# RTS5918 register map
Vendor: Realtek Semiconductor Corp.; Series: RTS5918 Series; File version: 1.00
CPU: ARMV8MML r0p0, little endian, MPU, FPU, VTOR, 3 interrupt priority bits, 8 SAU regions
Registers are 32-bit, read-write, reset 0x0 unless marked. A register's access mark holds for its fields unless they carry their own. Offsets are from the block's base; [hi:lo] are bit positions; {n}, {i} and the like mark numbered series; 'fields as' and 'values as' point back to an identical list.

## SYSTEM — System Controller
Base 0x40100000
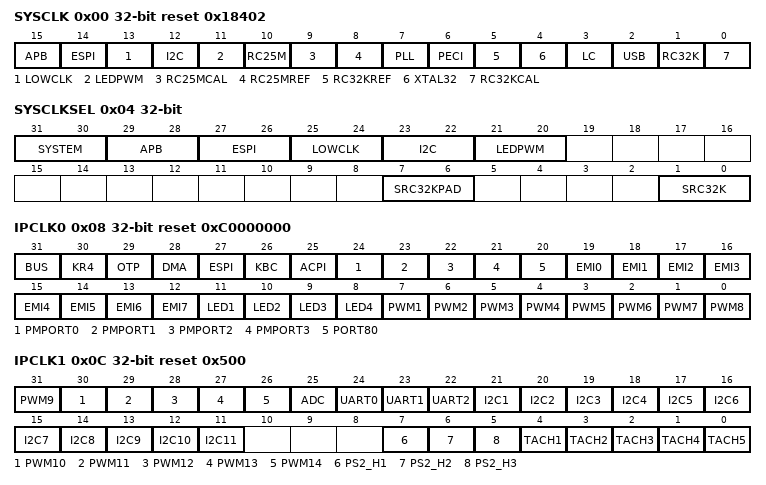
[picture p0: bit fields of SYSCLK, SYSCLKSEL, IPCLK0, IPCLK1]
0x00 SYSCLK reset 0x18402 — SYSCLK POWER ENABLE REGISTER
  [all] fields
    0=DISABLE (CLK_POW disable); 1=ENABLE (CLK_POW enable)
  [15] APB — APB Power
  [14] ESPI — ESPI Power
  [13] LOWCLK — LOWCLK Power
  [12] I2C — I2C Power
  [11] LEDPWM — LEDPWM Power
  [10] RC25M — RC25M Power
  [9] RC25MCAL — RC25M Calibration Power
  [8] RC25MREF — RC25MREF Power
  [7] PLL — PLL Power
  [6] PECI — PECI Power
  [5] RC32KREF — RC32KREF Power
  [4] XTAL32 — XTAL32 Power
  [3] LC — LC Power
  [2] USB — USB Power
  [1] RC32K — RC32K Power
  [0] RC32KCAL — RC32K Calibration Power
0x04 SYSCLKSEL — SYSTEM CLK SELECT REGISTER
  [31:30] SYSTEM — SYSTEM Clock Select
    0=RC25M (select RC25M); 1=PLL (select PLL)
  [29:28] APB — APB Clock Select
    0=RC25M (select RC25M); 1=PLL (select PLL)
  [27:26] ESPI — ESPI Clock Select
    0=RC25M (select RC25M); 1=PLL (select PLL)
  [25:24] LOWCLK — LOW Clock Select
    0=RC25M (select RC25M); 1=PLL (select PLL)
  [23:22] I2C — I2C Clock Select
    0=RC25M (select RC25M); 1=PLL (select PLL)
  [21:20] LEDPWM — select LEDPWM clock source
    0=RC25M (select RC25M); 1=PLL (select PLL); 2=RC32K (select RC32K); 3=XTAL (select XTAL)
  [7:6] SRC32KPAD — select 32K clock pad source
    0=RC32KIN (select RC32K in); 1=XTAL (select XTAL)
  [1:0] SRC32K — select 32K clock source
    0=RC32K (select RC32K); 1=RC25M/750 (select RC25M/750); 2=XTAL (select XTAL)
0x08 IPCLK0 reset 0xC0000000 — IP_CLOCK_0 POWER REGISTER
  [all] fields
    0=DISABLE (ip clock disable); 1=ENABLE (ip clock enable)
  [31] BUS — BUS IP Clock Power
  [30] KR4 — KR4 IP Clock Power
  [29] OTP — OTP IP Clock Power
  [28] DMA — DMA IP Clock Power
  [27] ESPI — ESPI IP Clock Power
  [26] KBC — KBC IP Clock Power
  [25] ACPI — ACPI IP Clock Power
  [24-n] PMPORT{n} (n=0..3) — PMPORT{n} IP Clock Power
  [20] PORT80 — PORT80 IP Clock Power
  [19-n] EMI{n} (n=0..7) — EMI{n} IP Clock Power
  [12-n] LED{n} (n=1..4) — LED{n} IP Clock Power
  [8-n] PWM{n} (n=1..7) — PWM{n} IP Clock Power
  [0] PWM8 — PWM8 IP Clock POWER
0x0C IPCLK1 reset 0x500 — IP_CLOCK_1 POWER EREGISTER
  [all] fields
    0=DISABLE (ip clock disable); 1=ENABLE (ip clock enable)
  [40-n] PWM{n} (n=9..14) — PWM{n} IP Clock Power
  [25] ADC — ADC IP Clock Power
  [24] UART0 — UART0 IP Clock Power
  [23] UART1 — UART1 IP Clock Power
  [22] UART2 — UART2 IP Clock Power
  [22-n] I2C{n} (n=1..11) — I2C{n} IP Clock Power
  [7] PS2_H1 — PS2_H1 IP Clock Power
  [6] PS2_H2 — PS2_H2 IP Clock Power
  [5] PS2_H3 — PS2_H3 IP Clock Power
  [5-n] TACH{n} (n=1..5) — TACH{n} IP Clock Power
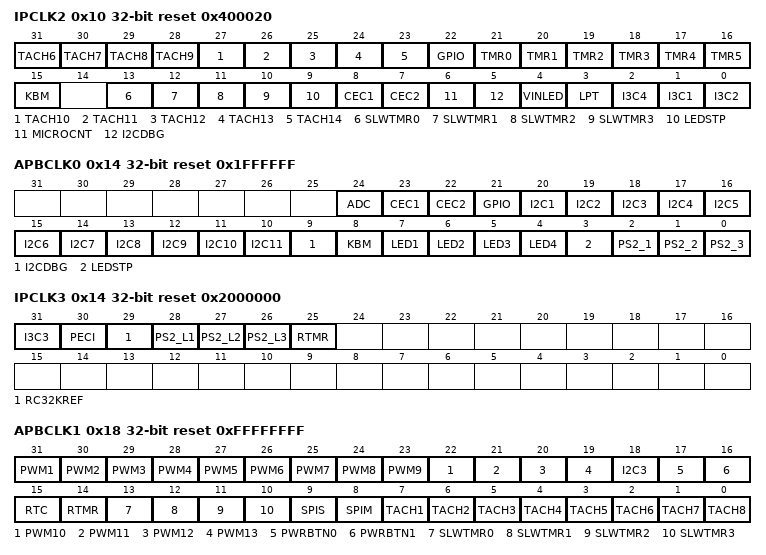
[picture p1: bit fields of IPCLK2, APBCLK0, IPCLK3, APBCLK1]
0x10 IPCLK2 reset 0x400020 — IP_CLOCK_2 POWER EREGISTER
  [all] fields
    0=DISABLE (ip clock disable); 1=ENABLE (ip clock enable)
  [37-n] TACH{n} (n=6..14) — TACH{n} IP Clock Power
  [22] GPIO — GPIO IP Clock Power
  [21-n] TMR{n} (n=0..5) — TMR{n} IP Clock Power
  [15] KBM — KBM IP Clock Power
  [13-n] SLWTMR{n} (n=0..3) — SLWTMR{n} IP Clock Power
  [9] LEDSTP — LEDSTP IP Clock Power
  [8] CEC1 — CEC1 IP Clock Power
  [7] CEC2 — CEC2 IP Clock Power
  [6] MICROCNT — MICROCNT IP Clock Power
  [5] I2CDBG — I2CDBG IP Clock Power
  [4] VINLED — VINLED IP Clock Power
  [3] LPT — LPT IP Clock Power
  [2] I3C4 — I3C4 IP Clock Power
  [1] I3C1 — I3C1 IP Clock Power
  [0] I3C2 — I3C2 IP Clock Power
0x14 APBCLK0 reset 0x1FFFFFF — APB_CLOCK_0 POWER EREGISTER
  [all] fields
    0=DISABLE (apb clock disable); 1=ENABLE (apb clock enable)
  [24] ADC — ADC APB Clock Power
  [23] CEC1 — CEC1 APB Clock Power
  [22] CEC2 — CEC2 APB Clock Power
  [21] GPIO — GPIO APB Clock Power
  [21-n] I2C{n} (n=1..11) — I2C{n} APB Clock Power
  [9] I2CDBG — I2CDBG APB Clock Power
  [8] KBM — KBM APB Clock Power
  [8-n] LED{n} (n=1..4) — LED{n} APB Clock Power
  [3] LEDSTP — LEDSTP APB Clock Power
  [2] PS2_1 — PS2_1 APB Clock Power
  [1] PS2_2 — PS2_2 APB Clock Power
  [0] PS2_3 — PS2_3 APB Clock Power
0x14 IPCLK3 reset 0x2000000 (alternate view of APBCLK0) — IP_CLOCK_3 POWER EREGISTER
  [all] fields
    0=DISABLE (ip clock disable); 1=ENABLE (ip clock enable)
  [31] I3C3 — I3C3 IP Clock Power
  [30] PECI — PECI IP Clock Power
  [29] RC32KREF — RC32KREF IP Clock Power
  [28] PS2_L1 — PS2_L1 Clock Power
  [27] PS2_L2 — PS2_L2 IP Clock Power
  [26] PS2_L3 — PS2_L3 IP Clock Power
  [25] RTMR — RTMR IP Clock Power
0x18 APBCLK1 reset 0xFFFFFFFF — APB_CLOCK_1 POWER EREGISTER
  [all] fields
    0=DISABLE (apb clock disable); 1=ENABLE (apb clock enable)
  [32-n] PWM{n} (n=1..13) — PWM{n} APB Clock Power
  [18] I2C3 — PWM14 APB Clock Power
  [17] PWRBTN0 — PWRBTN0 APB Clock Power
  [16] PWRBTN1 — PWRBTN1 APB Clock Power
  [15] RTC — RTC APB Clock Power
  [14] RTMR — RTMR APB Clock Power
  [13-n] SLWTMR{n} (n=0..3) — SLWTMR{n} APB Clock Power
  [9] SPIS — SPIS APB Clock Power
  [8] SPIM — SPIM APB Clock Power
  [8-n] TACH{n} (n=1..8) — TACH{n} APB Clock Power
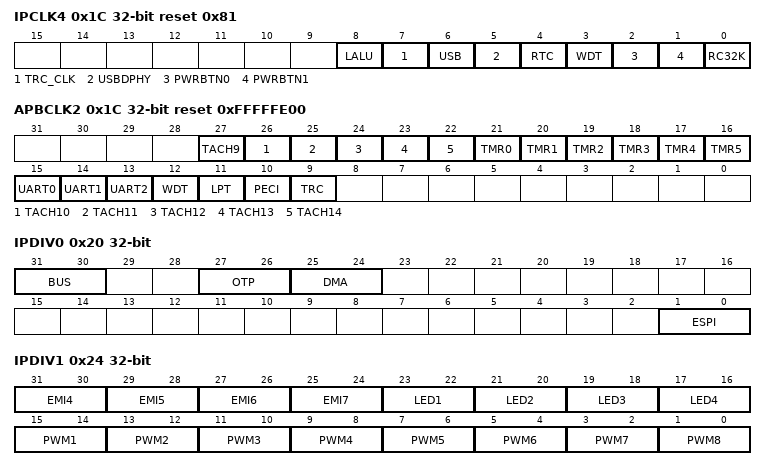
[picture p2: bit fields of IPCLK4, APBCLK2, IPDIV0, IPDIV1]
0x1C IPCLK4 reset 0x81 — IP_CLOCK_4 POWER EREGISTER
  [all] fields
    0=DISABLE (ip clock disable); 1=ENABLE (ip clock enable)
  [8] LALU — LALU IP Clock Power
  [7] TRC_CLK — TRC_CLK IP Clock Power
  [6] USB — USB IP Clock Power
  [5] USBDPHY — USBDPHY IP Clock Power
  [4] RTC — RTC IP Clock Power
  [3] WDT — WDT Clock Power
  [2] PWRBTN0 — PWRBTN0 IP Clock Power
  [1] PWRBTN1 — PWRBTN1 IP Clock Power
  [0] RC32K — RC32K IP Clock Power
0x1C APBCLK2 reset 0xFFFFFE00 (alternate view of IPCLK4) — APB_CLOCK_2 POWER EREGISTER
  [all] fields
    0=DISABLE (apb clock disable); 1=ENABLE (apb clock enable)
  [36-n] TACH{n} (n=9..14) — TACH{n} APB Clock Power
  [21-n] TMR{n} (n=0..5) — TMR{n} APB Clock Power
  [15] UART0 — UART0 APB Clock Power
  [14] UART1 — UART1 APB Clock Power
  [13] UART2 — UART2 APB Clock Power
  [12] WDT — WDT APB Clock Power
  [11] LPT — LPT APB Clock Power
  [10] PECI — PECI APB Clock Power
  [9] TRC — TRC APB Clock Power
0x20 IPDIV0 — IP_CLOCK_DIVIDER_0 REGISTER
  [all] fields
    0=DIV1 (ip clock divide 1); 1=DIV2 (ip clock divide 2); 2=DIV4 (ip clock divide 4); 3=DIV8 (ip clock divide 8)
  [31:30] BUS — BUS IP Clock Divider
  [27:26] OTP — OTP IP Clock Divider
  [25:24] DMA — DMA IP Clock Divider
  [1:0] ESPI — ESPI IP Clock Divider
0x24 IPDIV1 — IP_CLOCK_DIVIDER_1 REGISTER
  [39-2n:38-2n] EMI{n} (n=4..7) — EMI{n} IP Clock Divider
    values as the fields of IPDIV0
  [25-2n:24-2n] LED{n} (n=1..4) — LED{n} IP Clock Divider
    0=DIV780 (ip clock divide 780); 1=DIV2 (ip clock divide 2); 2=DIV1 (ip clock divide 1)
  [17-2n:16-2n] PWM{n} (n=1..8) — PWM{n} IP Clock Divider
    values as LED1
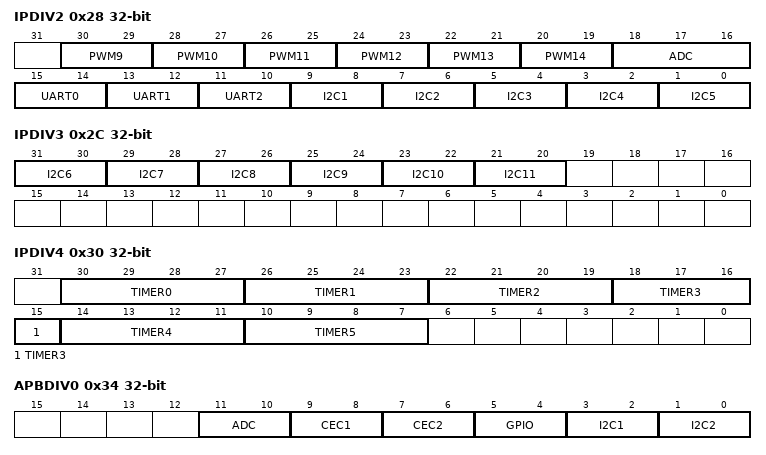
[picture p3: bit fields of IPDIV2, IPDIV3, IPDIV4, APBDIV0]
0x28 IPDIV2 — IP_CLOCK_DIVIDER_2 REGISTER
  [48-2n:47-2n] PWM{n} (n=9..14) — PWM{n} IP Clock Divider
    values as IPDIV1.LED1
  [18:16] ADC — ADC IP Clock Divider
    {v}=DIV{v+1} (ip clock divide {v+1}) (v=0..3); 4=DIV6 (ip clock divide 6); 5=DIV8 (ip clock divide 8); 6=DIV12 (ip clock divide 12); 7=DIV16 (ip clock divide 16)
  [15:14] UART0 — UART0 IP Clock Divider
    values as the fields of IPDIV0
  [13:12] UART1 — UART1 IP Clock Divider
    values as the fields of IPDIV0
  [11:10] UART2 — UART2 IP Clock Divider
    values as the fields of IPDIV0
  [11-2n:10-2n] I2C{n} (n=1..5) — I2C{n} IP Clock Divider
    values as the fields of IPDIV0
0x2C IPDIV3 — IP_CLOCK_DIVIDER_3 REGISTER
  [all] fields
    values as the fields of IPDIV0
  [43-2n:42-2n] I2C{n} (n=6..11) — I2C{n} IP Clock Divider
0x30 IPDIV4 — IP_CLOCK_DIVIDER_4 REGISTER
  [all] fields
    0=DIV1 (ip clock divide 1); 1=DIV2 (ip clock divide 2); 2=DIV4 (ip clock divide 4); 3=DIV8 (ip clock divide 8); 4=DIV8 (ip clock divide 16); 5=DIV8 (ip clock divide 32); 6=DIV8 (ip clock divide 64); 7=DIV8 (ip clock divide 128); 8=DIV8 (ip clock divide 256)
  [30-4n:27-4n] TIMER{n} (n=0..5) — TIMER{n} IP Clock Divider
0x34 APBDIV0 — APB_CLOCK_DIVIDER_0 REGISTER
  [all] fields
    0=DIV1 (apb clock divide 1); 1=DIV2 (apb clock divide 2); 2=DIV4 (apb clock divide 4); 3=DIV8 (apb clock divide 8)
  [11:10] ADC — ADC APB Clock Divider
  [9:8] CEC1 — CEC1 APB Clock Divider
  [7:6] CEC2 — CEC2 APB Clock Divider
  [5:4] GPIO — GPIO APB Clock Divider
  [3:2] I2C1 — I2C1 APB Clock Divider
  [1:0] I2C2 — I2C2 APB Clock Divider
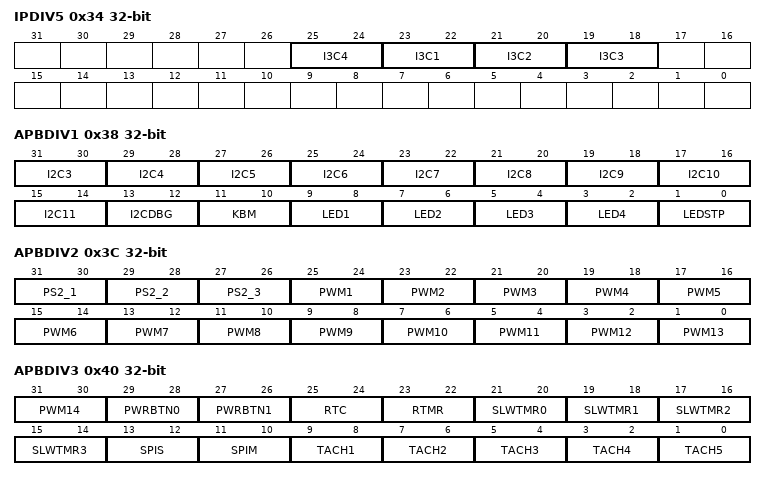
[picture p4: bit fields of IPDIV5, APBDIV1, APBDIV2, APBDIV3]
0x34 IPDIV5 (alternate view of APBDIV0) — IP_CLOCK_DIVIDER_5 REGISTER
  [all] fields
    values as the fields of IPDIV0
  [25:24] I3C4 — I3C4 IP Clock Divider
  [23:22] I3C1 — I3C1 IP Clock Divider
  [21:20] I3C2 — I3C2 IP Clock Divider
  [19:18] I3C3 — I3C3 IP Clock Divider
0x38 APBDIV1 — APB_CLOCK_DIVIDER_1 REGISTER
  [all] fields
    values as the fields of APBDIV0
  [37-2n:36-2n] I2C{n} (n=3..11) — I2C{n} APB Clock Divider
  [13:12] I2CDBG — I2CDBG APB Clock Divider
  [11:10] KBM — KBM APB Clock Divider
  [11-2n:10-2n] LED{n} (n=1..4) — LED{n} APB Clock Divider
  [1:0] LEDSTP — LEDSTP APB Clock Divider
0x3C APBDIV2 — APB_CLOCK_DIVIDER_2 REGISTER
  [all] fields
    values as the fields of APBDIV0
  [31:30] PS2_1 — PS2_1 APB Clock Divider
  [29:28] PS2_2 — PS2_2 APB Clock Divider
  [27:26] PS2_3 — PS2_3 APB Clock Divider
  [27-2n:26-2n] PWM{n} (n=1..13) — PWM{n} APB Clock Divider
0x40 APBDIV3 — APB_CLOCK_DIVIDER_3 REGISTER
  [all] fields
    values as the fields of APBDIV0
  [31:30] PWM14 — PWM14 APB Clock Divider
  [29:28] PWRBTN0 — PWRBTN0 APB Clock Divider
  [27:26] PWRBTN1 — PWRBTN1 APB Clock Divider
  [25:24] RTC — RTC APB Clock Divider
  [23:22] RTMR — RTMR APB Clock Divider
  [21-2n:20-2n] SLWTMR{n} (n=0..3) — SLWTMR{n} APB Clock Divider
  [13:12] SPIS — SPIS APB Clock Divider
  [11:10] SPIM — SPIM APB Clock Divider
  [11-2n:10-2n] TACH{n} (n=1..5) — TACH{n} APB Clock Divider
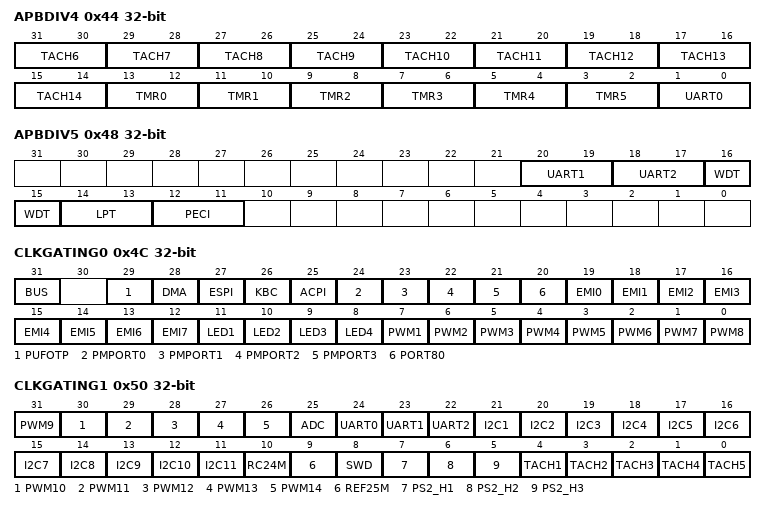
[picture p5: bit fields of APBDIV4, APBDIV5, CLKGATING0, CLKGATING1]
0x44 APBDIV4 — APB_CLOCK_DIVIDER_4 REGISTER
  [all] fields
    values as the fields of APBDIV0
  [43-2n:42-2n] TACH{n} (n=6..14) — TACH{n} APB Clock Divider
  [13-2n:12-2n] TMR{n} (n=0..5) — TMR{n} APB Clock Divider
  [1:0] UART0 — UART0 APB Clock Divider
0x48 APBDIV5 — APB_CLOCK_DIVIDER_5 REGISTER
  [all] fields
    values as the fields of APBDIV0
  [20:19] UART1 — UART1 APB Clock Divider
  [18:17] UART2 — UART2 APB Clock Divider
  [16:15] WDT — WDT APB Clock Divider
  [14:13] LPT — LPT APB Clock Divider
  [12:11] PECI — PECI APB Clock Divider
0x48 IPDIV6 (alternate view of APBDIV5) — IP_CLOCK_DIVIDER_6 REGISTER
  [6] USB — USB IP Clock Divider
    0=DIV1 (ip clock divide 1); 1=DIV2 (ip clock divide 2)
0x4C CLKGATING0 — IP_CLOCK_GATING_0 EREGISTER
  [all] fields
    0=DISABLE (IP clock pass); 1=ENABLE (IP clock gating)
  [31] BUS — BUS IP Clock Gating
  [29] PUFOTP — PUFOTP IP Clock Gating
  [28] DMA — DMA IP Clock Gating
  [27] ESPI — ESPI IP Clock Gating
  [26] KBC — KBC IP Clock Gating
  [25] ACPI — ACPI IP Clock Gating
  [24-n] PMPORT{n} (n=0..3) — PMPORT{n} IP Clock Gating
  [20] PORT80 — PORT80 IP Clock Gating
  [19-n] EMI{n} (n=0..7) — EMI{n} IP Clock Gating
  [12-n] LED{n} (n=1..4) — LED{n} IP Clock Gating
  [8-n] PWM{n} (n=1..8) — PWM{n} IP Clock Gating
0x50 CLKGATING1 — IP_CLOCK_GATING_1 EREGISTER
  [all] fields
    0=DISABLE (IP clock pass); 1=ENABLE (IP clock gating)
  [40-n] PWM{n} (n=9..14) — PWM{n} IP Clock Gating
  [25] ADC — ADC IP Clock Gating
  [24] UART0 — UART0 IP Clock Gating
  [23] UART1 — UART1 IP Clock Gating
  [22] UART2 — UART2 IP Clock Gating
  [22-n] I2C{n} (n=1..11) — I2C{n} IP Clock Gating
  [10] RC24M — RC24M IP Clock Gating
  [9] REF25M — REF25M IP Clock Gating
  [8] SWD — SWD IP Clock Gating
  [7] PS2_H1 — PS2_H1 IP Clock Gating
  [6] PS2_H2 — PS2_H2 IP Clock Gating
  [5] PS2_H3 — PS2_H3 IP Clock Gating
  [5-n] TACH{n} (n=1..5) — TACH{n} IP Clock Gating
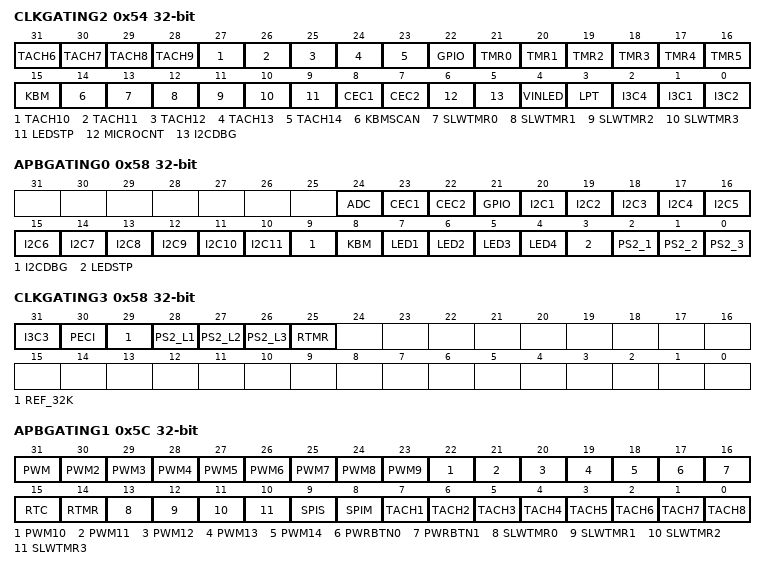
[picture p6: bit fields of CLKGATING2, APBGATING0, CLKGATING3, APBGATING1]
0x54 CLKGATING2 — IP_CLOCK_GATING_2 EREGISTER
  [all] fields
    0=DISABLE (IP clock pass); 1=ENABLE (IP clock gating)
  [37-n] TACH{n} (n=6..14) — TACH{n} IP Clock Gating
  [22] GPIO — GPIO IP Clock Gating
  [21-n] TMR{n} (n=0..5) — TMR{n} IP Clock Gating
  [15] KBM — KBM IP Clock Gating
  [14] KBMSCAN — KBMSCAN IP Clock Gating
  [13-n] SLWTMR{n} (n=0..3) — SLWTMR{n} IP Clock Gating
  [9] LEDSTP — LEDSTP IP Clock Gating
  [8] CEC1 — CEC1 IP Clock Gating
  [7] CEC2 — CEC2 IP Clock Gating
  [6] MICROCNT — MICROCNT IP Clock Gating
  [5] I2CDBG — I2CDBG IP Clock Gating
  [4] VINLED — VINLED IP Clock Gating
  [3] LPT — LPT IP Clock Gating
  [2] I3C4 — I3C4 IP Clock Gating
  [1] I3C1 — I3C1 IP Clock Gating
  [0] I3C2 — I3C2 IP Clock Gating
0x58 APBGATING0 — APB_CLOCK_GATING_0 EREGISTER
  [all] fields
    0=DISABLE (APB clock pass); 1=ENABLE (APB clock gating)
  [24] ADC — ADC APB Clock Gating
  [23] CEC1 — CEC1 APB Clock Gating
  [22] CEC2 — CEC2 APB Clock Gating
  [21] GPIO — GPIO APB Clock Gating
  [21-n] I2C{n} (n=1..11) — I2C{n} APB Clock Gating
  [9] I2CDBG — I2CDBG APB Clock Gating
  [8] KBM — KBM APB Clock Gating
  [8-n] LED{n} (n=1..4) — LED{n} APB Clock Gating
  [3] LEDSTP — LEDSTP APB Clock Gating
  [2] PS2_1 — PS2_1 APB Clock Gating
  [1] PS2_2 — PS2_2 APB Clock Gating
  [0] PS2_3 — PS2_3 APB Clock Gating
0x58 CLKGATING3 (alternate view of APBGATING0) — IP_CLOCK_GATING_3 EREGISTER
  [all] fields
    0=DISABLE (IP clock pass); 1=ENABLE (IP clock gating)
  [31] I3C3 — I3C3 IP Clock Gating
  [30] PECI — PECI IP Clock Gating
  [29] REF_32K — REF_32K IP Clock Gating
  [28] PS2_L1 — PS2_L1 IP Clock Gating
  [27] PS2_L2 — PS2_L2 IP Clock Gating
  [26] PS2_L3 — PS2_L3 IP Clock Gating
  [25] RTMR — RTMR IP Clock Gating
0x5C APBGATING1 — APB_CLOCK_GATING_1 EREGISTER
  [all] fields
    0=DISABLE (APB clock pass); 1=ENABLE (APB clock gating)
  [31] PWM — PWM1 APB Clock Gating
  [32-n] PWM{n} (n=2..14) — PWM{n} APB Clock Gating
  [17] PWRBTN0 — PWRBTN0 APB Clock Gating
  [16] PWRBTN1 — PWRBTN1 APB Clock Gating
  [15] RTC — RTC APB Clock Gating
  [14] RTMR — RTMR APB Clock Gating
  [13-n] SLWTMR{n} (n=0..3) — SLWTMR{n} APB Clock Gating
  [9] SPIS — SPIS APB Clock Gating
  [8] SPIM — SPIM APB Clock Gating
  [8-n] TACH{n} (n=1..8) — TACH{n} APB Clock Gating
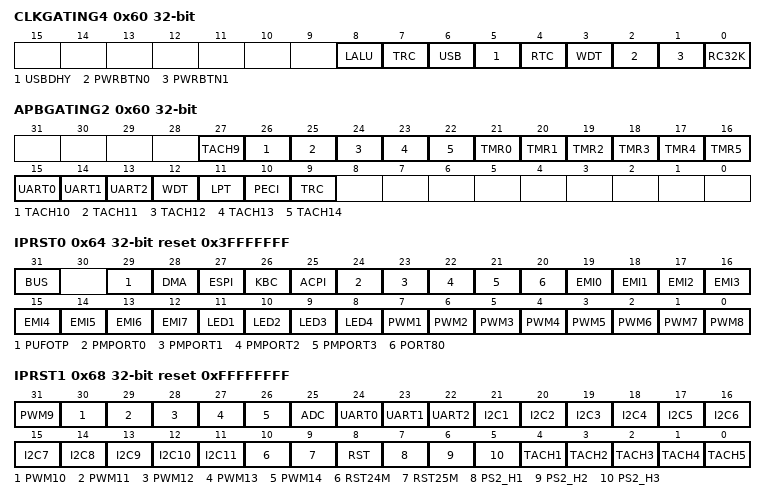
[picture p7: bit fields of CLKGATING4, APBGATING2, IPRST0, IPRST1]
0x60 CLKGATING4 — IP_CLOCK_GATING_4 EREGISTER
  [all] fields
    0=DISABLE (IP clock pass); 1=ENABLE (IP clock gating)
  [8] LALU — LALU IP Clock Gating
  [7] TRC — TRC IP Clock Gating
  [6] USB — USB IP Clock Gating
  [5] USBDHY — USBDHY IP Clock Gating
  [4] RTC — RTC IP Clock Gating
  [3] WDT — WDT IP Clock Gating
  [2] PWRBTN0 — PWRBTN0 IP Clock Gating
  [1] PWRBTN1 — PWRBTN1 IP Clock Gating
  [0] RC32K — RC32K IP Clock Gating
0x60 APBGATING2 (alternate view of CLKGATING4) — APB_CLOCK_GATING_2 EREGISTER
  [all] fields
    0=DISABLE (APB clock pass); 1=ENABLE (APB clock gating)
  [36-n] TACH{n} (n=9..14) — TACH{n} APB Clock Gating
  [21-n] TMR{n} (n=0..5) — TMR{n} APB Clock Gating
  [15] UART0 — UART0 APB Clock Gating
  [14] UART1 — UART1 APB Clock Gating
  [13] UART2 — UART2 APB Clock Gating
  [12] WDT — WDT APB Clock Gating
  [11] LPT — LPT APB Clock Gating
  [10] PECI — PECI APB Clock Gating
  [9] TRC — TRC APB Clock Gating
0x64 IPRST0 reset 0x3FFFFFFF — IP_RESET_0 EREGISTER
  [31] BUS write-1-clears — BUS IP Reset
    0=NONE; 1=RESET (RESET BUS IP)
  [29] PUFOTP — PUFOTP IP Reset
    0=RESET (IP RESET); 1=IDLE (IP Idle)
  [28] DMA — DMA IP Reset
    0=RESET (IP RESET); 1=IDLE (IP Idle)
  [27] ESPI — ESPI IP Reset
    0=RESET (IP RESET); 1=IDLE (IP Idle)
  [26] KBC — KBC IP Reset
    0=RESET (IP RESET); 1=IDLE (IP Idle)
  [25] ACPI — ACPI IP Reset
    0=RESET (IP RESET); 1=IDLE (IP Idle)
  [24-n] PMPORT{n} (n=0..3) — PMPORT{n} IP Reset
    0=RESET (IP RESET); 1=IDLE (IP Idle)
  [20] PORT80 — PORT80 IP Reset
    0=RESET (IP RESET); 1=IDLE (IP Idle)
  [19-n] EMI{n} (n=0..7) — EMI{n} IP Reset
    0=RESET (IP RESET); 1=IDLE (IP Idle)
  [12-n] LED{n} (n=1..4) — LED{n} IP Reset
    0=RESET (IP RESET); 1=IDLE (IP Idle)
  [8-n] PWM{n} (n=1..8) — PWM{n} IP Reset
    0=RESET (IP RESET); 1=IDLE (IP Idle)
0x68 IPRST1 reset 0xFFFFFFFF — IP_RESET_1 EREGISTER
  [all] fields
    0=RESET (IP RESET); 1=IDLE (IP Idle)
  [40-n] PWM{n} (n=9..14) — PWM{n} IP Reset
  [25] ADC — ADC IP Reset
  [24] UART0 — UART0 IP Reset
  [23] UART1 — UART1 IP Reset
  [22] UART2 — UART2 IP Reset
  [22-n] I2C{n} (n=1..11) — I2C{n} IP Reset
  [10] RST24M — RST24M IP Reset
  [9] RST25M — RST25M IP Reset
  [8] RST — RST IP Reset
  [7] PS2_H1 — PS2_H1 IP Reset
  [6] PS2_H2 — PS2_H2 IP Reset
  [5] PS2_H3 — PS2_H3 IP Reset
  [5-n] TACH{n} (n=1..5) — TACH{n} IP Reset
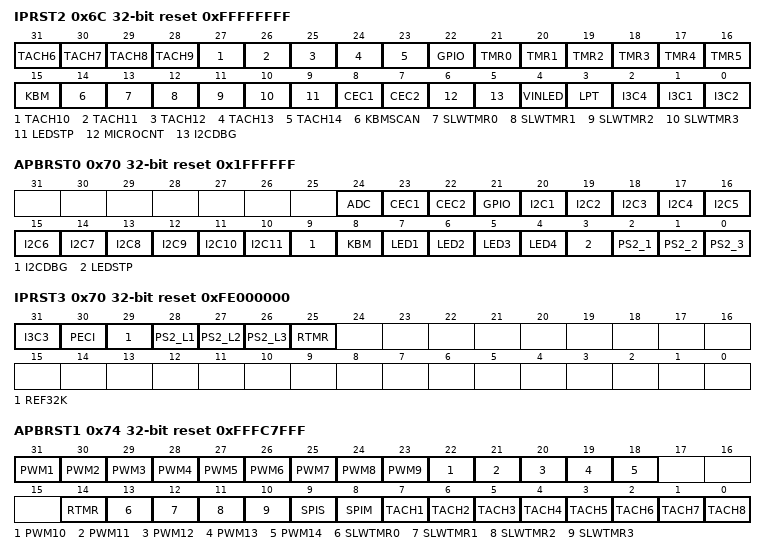
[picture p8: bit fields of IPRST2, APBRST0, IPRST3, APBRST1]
0x6C IPRST2 reset 0xFFFFFFFF — IP_RESET_2 EREGISTER
  [all] fields
    0=RESET (IP RESET); 1=IDLE (IP Idle)
  [37-n] TACH{n} (n=6..14) — TACH{n} IP Reset
  [22] GPIO — GPIO IP Reset
  [21-n] TMR{n} (n=0..5) — TMR{n} IP Reset
  [15] KBM — KBM IP Reset
  [14] KBMSCAN — KBMSCAN IP Reset
  [13-n] SLWTMR{n} (n=0..3) — SLWTMR{n} IP Reset
  [9] LEDSTP — LEDSTP IP Reset
  [8] CEC1 — CEC1 IP Reset
  [7] CEC2 — CEC2 IP Reset
  [6] MICROCNT — MICROCNT IP Reset
  [5] I2CDBG — I2CDBG IP Reset
  [4] VINLED — VINLED IP Reset
  [3] LPT — LPT IP Reset
  [2] I3C4 — I3C4 IP Reset
  [1] I3C1 — I3C1 IP Reset
  [0] I3C2 — I3C2 IP Reset
0x70 APBRST0 reset 0x1FFFFFF — APB_RESET_0 EREGISTER
  [all] fields
    0=RESET (APB RESET); 1=IDLE (APB IDLE)
  [24] ADC — ADC APB Reset
  [23] CEC1 — CEC1 APB Reset
  [22] CEC2 — CEC2 APB Reset
  [21] GPIO — GPIO APB Reset
  [21-n] I2C{n} (n=1..11) — I2C{n} APB Reset
  [9] I2CDBG — I2CDBG APB Reset
  [8] KBM — KBM APB Reset
  [8-n] LED{n} (n=1..4) — LED{n} APB Reset
  [3] LEDSTP — LEDSTP APB Reset
  [2] PS2_1 — PS2_1 APB Reset
  [1] PS2_2 — PS2_2 APB Reset
  [0] PS2_3 — PS2_3 APB Reset
0x70 IPRST3 reset 0xFE000000 (alternate view of APBRST0) — IP_RESET_3 EREGISTER
  [all] fields
    0=RESET (IP RESET); 1=IDLE (IP Idle)
  [31] I3C3 — I3C3 IP Reset
  [30] PECI — PECI IP Reset
  [29] REF32K — REF32K IP Reset
  [28] PS2_L1 — PS2_L1 IP Resetg
  [27] PS2_L2 — PS2_L2 IP Reset
  [26] PS2_L3 — PS2_L3 IP Reset
  [25] RTMR — RTMR IP Reset
0x74 APBRST1 reset 0xFFFC7FFF — APB_RESET_1 EREGISTER
  [all] fields
    0=RESET (APB RESET); 1=IDLE (APB IDLE)
  [32-n] PWM{n} (n=1..14) — PWM{n} APB Reset
  [14] RTMR — RTMR APB Reset
  [13-n] SLWTMR{n} (n=0..3) — SLWTMR{n} APB Reset
  [9] SPIS — SPIS APB Reset
  [8] SPIM — SPIM APB Reset
  [8-n] TACH{n} (n=1..8) — TACH{n} APB Reset
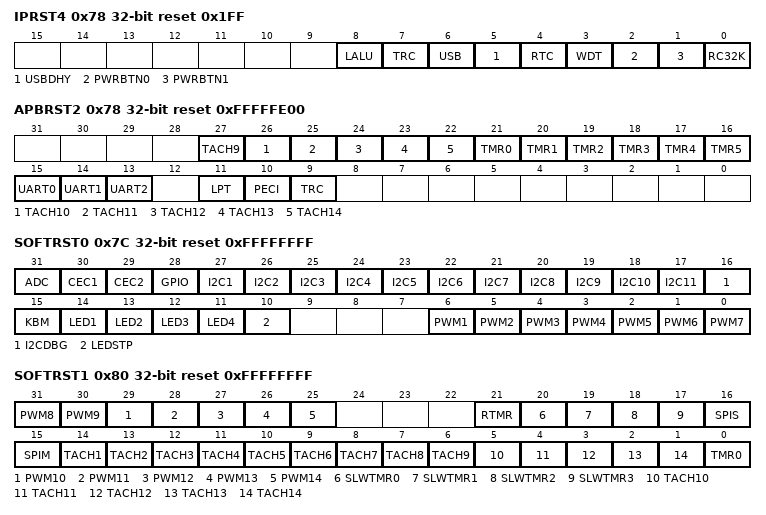
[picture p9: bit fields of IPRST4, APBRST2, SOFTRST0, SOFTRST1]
0x78 IPRST4 reset 0x1FF — IP_RESET_4 EREGISTER
  [all] fields
    0=RESET (IP RESET); 1=IDLE (IP Idle)
  [8] LALU — LALU IP Reset
  [7] TRC — TRC IP Reset
  [6] USB — USB IP Reset
  [5] USBDHY — USBDHY IP Reset
  [4] RTC — RTC IP Reset
  [3] WDT — WDT IP Reset
  [2] PWRBTN0 — PWRBTN0 IP Reset
  [1] PWRBTN1 — PWRBTN1 IP Reset
  [0] RC32K — RC32K IP Reset
0x78 APBRST2 reset 0xFFFFFE00 (alternate view of IPRST4) — APB_RESET_2 EREGISTER
  [all] fields
    0=RESET (APB RESET); 1=IDLE (APB IDLE)
  [36-n] TACH{n} (n=9..14) — TACH{n} APB Reset
  [21-n] TMR{n} (n=0..5) — TMR{n} APB Reset
  [15] UART0 — UART0 APB Reset
  [14] UART1 — UART1 APB Reset
  [13] UART2 — UART2 APB Reset
  [11] LPT — LPT APB Reset
  [10] PECI — PECI APB Reset
  [9] TRC — TRC APB Reset
0x7C SOFTRST0 reset 0xFFFFFFFF — SOFT_RESET_0 EREGISTER
  [all] fields
    0=RESET (soft reset); 1=IDLE (soft idle)
  [31] ADC — ADC Soft Reset
  [30] CEC1 — CEC1 Soft Reset
  [29] CEC2 — CEC2 Soft Reset
  [28] GPIO — GPIO Soft Reset
  [28-n] I2C{n} (n=1..11) — I2C{n} Soft Reset
  [16] I2CDBG — I2CDBG Soft Reset
  [15] KBM — KBM Soft Reset
  [15-n] LED{n} (n=1..4) — LED{n} Soft Reset
  [10] LEDSTP — LEDSTP Soft Reset
  [7-n] PWM{n} (n=1..7) — PWM{n} Soft Reset
0x80 SOFTRST1 reset 0xFFFFFFFF — SOFT_RESET_1 EREGISTER
  [all] fields
    0=RESET (soft reset); 1=IDLE (soft idle)
  [39-n] PWM{n} (n=8..14) — PWM{n} Soft Reset
  [21] RTMR — RTMR Soft Reset
  [20-n] SLWTMR{n} (n=0..3) — SLWTMR{n} Soft Reset
  [16] SPIS — SPIS Soft Reset
  [15] SPIM — SPIM Soft Reset
  [15-n] TACH{n} (n=1..14) — TACH{n} Soft Reset
  [0] TMR0 — TMR0 Soft Reset
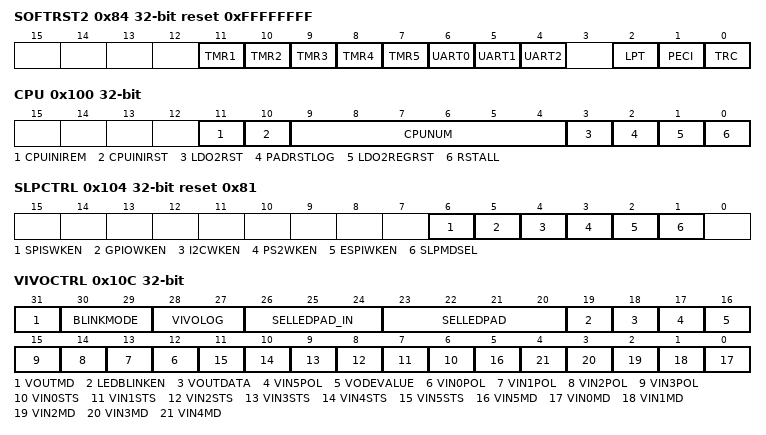
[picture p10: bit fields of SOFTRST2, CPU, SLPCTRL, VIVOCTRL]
0x84 SOFTRST2 reset 0xFFFFFFFF — SOFT_RESET_2 EREGISTER
  [all] fields
    0=RESET (soft reset); 1=IDLE (soft idle)
  [12-n] TMR{n} (n=1..5) — TMR{n} Soft Reset
  [6] UART0 — UART0 Soft Reset
  [5] UART1 — UART1 Soft Reset
  [4] UART2 — UART2 Soft Reset
  [2] LPT — LPT Soft Reset
  [1] PECI — PECI Soft Reset
  [0] TRC — TRC Soft Reset
0x100 CPU
  [11] CPUINIREM — CPU Initial Access Address Remain
    0=NONE; 1=REMAIN (Remain CPU initail access address)
  [10] CPUINIRST write-1-clears — CPU Initial Access Address Reset
    0=NONE; 1=RESET (Reset address)
  [9:4] CPUNUM
  [3] LDO2RST write-1-clears — LDO2 Reset
    0=NONE; 1=RESET (Reset LDO2)
  [2] PADRSTLOG write-1-clears — Pad Reset Log
    0=NONE (pad reset is not triggered); 1=RESETED (pad reset is triggered)
  [1] LDO2REGRST write-1-clears — Reset LDO2 Register
    0=NONE; 1=RESET (Reset LDO2)
  [0] RSTALL write-1-clears — Soft Reset All Regsiters
    0=NONE; 1=RESET (Reset all registers)
0x104 SLPCTRL reset 0x81 — SYSTEM SLEEP CONTROL REGISTER
  [6] SPISWKEN — SPIS Wake-up Enable
    0=DISABLE (Disable SPIS wake-up); 1=ENABLE (Enable SPIS wake-up)
  [5] GPIOWKEN — GPIO Wake-up Enable
    0=DISABLE (Disable GPIO wake-up); 1=ENABLE (Enable GPIO wake-up)
  [4] I2CWKEN — I2C Wake-up Enable
    0=DISABLE (Disable I2C wake-up); 1=ENABLE (Enable I2C wake-up)
  [3] PS2WKEN — PS2 Wake-up Enable
    0=DISABLE (Disable PS2 wake-up); 1=ENABLE (Enable PS2 wake-up)
  [2] ESPIWKEN — eSPI Wake-up Enable
    0=DISABLE (Disable eSPI wake-up); 1=ENABLE (Enable eSPI wake-up)
  [1] SLPMDSEL — Sleep Mode Selection
    0=LIGHT_SLEEP (Using Light-sleep Mode); 1=HEAVRY_SLEEP (Using Heavry-sleep Mode)
0x10C VIVOCTRL — VINVOUT CONTROL REGISTER
  [31] VOUTMD — VOUT Mode Selection
    0=VOUT (Using VOUT function); 1=GPIO (Using GPIO function)
  [30:29] BLINKMODE ro — Select led blink mode
    0=LOW (Always output low); 1=HIGH (Always output high); 2=BLINKING
  [28:27] VIVOLOG — VIN VOUT LOG
  [26:24] SELLEDPAD_IN — Select Vin source for hardware LED blinking
    0=Vin4 as reference; 1=Vin3 as reference; 2=Vin2 as reference; 3=Vin1 as reference; 4=Vin0 as reference
  [23:20] SELLEDPAD — Select LED pad out force blinking
    1=GPIO001 (led blink GPIO001); 2=GPIO020 (led blink GPIO020); 4=GPIO059 (led blink GPIO059); 8=GPIO138 (led blink GPIO138)
  [19] LEDBLINKEN — Enable H/W led blink after select Vin log
    0=DISABLE (led blink disable); 1=ENABLE (led blink enable)
  [18] VOUTDATA — Slect VOUT data
    0=LOW (VOUT data is LOW); 1=HIGH (VOUT data is HIGH)
  [17] VIN5POL — VIN5 Polarity
    0=RISING (Rising-edge detection); 1=FALLING (Falling-edge detection)
  [16] VODEVALUE — VOUT default value
    0=LOW (VOUT default is LOW); 1=HIGH (VOUT default is HIGH)
  [n+12] VIN{n}POL (n=0..3) — VIN{n} Polarity
    values as VIN5POL
  [n+6] VIN{n}STS ro (n=0..5) — VIN{n} Status
    0=NOTHING; 1=DETECTED (VIN{n} falling/rising-edge is detected)
  [5] VIN5MD — VI5 Mode Selection
    0=GPIO (Select GPIO Function); 1=VIN (Select VIN function)
  [n] VIN{n}MD (n=0..4) — VIN{n} Mode Selection
    0=GPIO (Select GPIO Function); 1=VIN (Select VIN function)
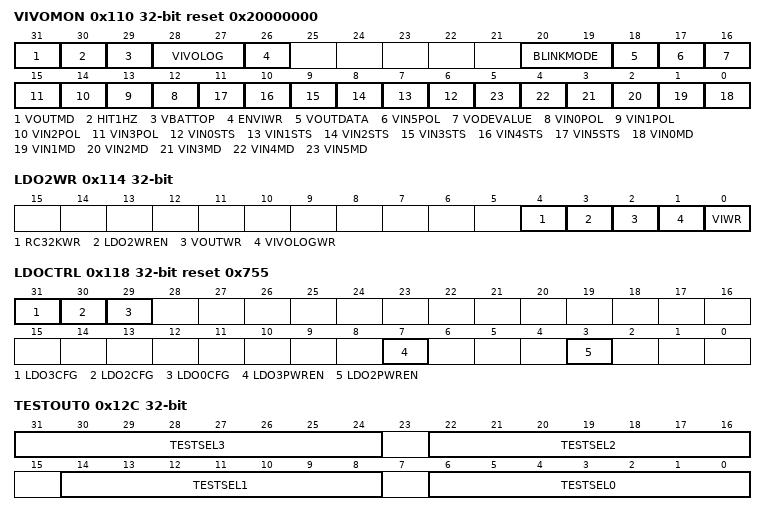
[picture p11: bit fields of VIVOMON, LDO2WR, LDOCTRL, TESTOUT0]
0x110 VIVOMON ro reset 0x20000000 — VIN VOUT MONITOR REGISTER
  [31] VOUTMD — VOUT MODE SELECTION MONITOR
  [30] HIT1HZ — 1 Hz Timer Status
  [29] VBATTOP — VBAT top status out data
  [28:27] VIVOLOG — VIN VOUT LOG Monitor
  [26] ENVIWR — Enable VIN Register Write Monitor
  [20:19] BLINKMODE — Led Blink Mode Status
  [18] VOUTDATA — Select VOUT Data Monitor
  [17] VIN5POL — VIN5 Polarity Monitor
  [16] VODEVALUE — VOUT Default Value
  [n+12] VIN{n}POL (n=0..3) — VIN{n} Polarity Monitor
  [n+6] VIN{n}STS (n=0..5) — VIN{n} Status Monitor
  [n] VIN{n}MD (n=0..5) — VIN{n} Mode Monitor
0x114 LDO2WR — LDO2 WRITE REGISTER
  [4] RC32KWR — Write RC32K Register Enable
    0=DISALBE (Disable write RC32K register); 1=ENABLE (Enable write RC32K register)
  [3] LDO2WREN — Write LDO2 Register Enable
    0=DISALBE (Disable write LDO2 register); 1=ENABLE (Enable write LDO2 register)
  [2] VOUTWR — Write VOUT Register Enable
    0=DISALBE (Disable write VOUT register); 1=ENABLE (Enable write VOUT register)
  [1] VIVOLOGWR — Write VIN VOUT LOG Register Enable
    0=DISALBE (Disable write VIN VOUT LOG register); 1=ENABLE (Enable write VIN VOUT LOG register)
  [0] VIWR — Write VIN Register Enable
    0=DISALBE (Disable write VIN register); 1=ENABLE (Enable write VIN register)
0x118 LDOCTRL reset 0x755 — LDO CONTROL REGISTER
  [31] LDO3CFG — LDO3 configuration select
    0=DEFAULT (Default Value); 1=ENABLE (Enable FW write data to register)
  [30] LDO2CFG — LDO2 configuration select
    values as LDO3CFG
  [29] LDO0CFG — LDO0 configuration select
    values as LDO3CFG
  [7] LDO3PWREN — LDO3 Power Enable
    0=DISALBE (Disable LDO3 power); 1=ENABLE (ENABLE LDO3 power)
  [3] LDO2PWREN — LDO2 Power Enable
    0=DISALBE (Disable LDO2 power); 1=ENABLE (ENABLE LDO2 power)
0x12C TESTOUT0
  [31:24] TESTSEL3 — TEST OUT 3 SEL
  [22:16] TESTSEL2 — TEST OUT 2 SEL
  [14:8] TESTSEL1 — TEST OUT 1 SEL
  [6:0] TESTSEL0 — TEST OUT 0 SEL
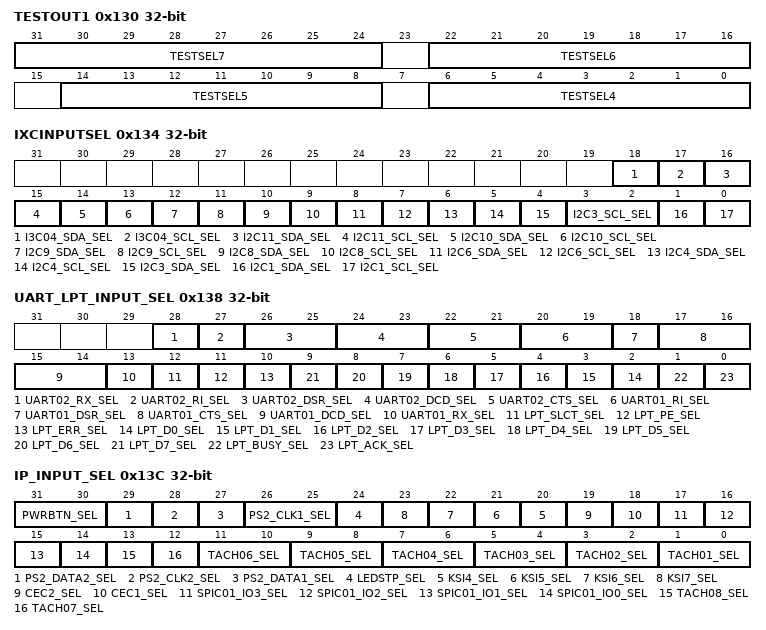
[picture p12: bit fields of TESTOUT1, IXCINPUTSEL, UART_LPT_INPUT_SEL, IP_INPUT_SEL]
0x130 TESTOUT1
  [31:24] TESTSEL7 — TEST OUT 7 SEL
  [22:16] TESTSEL6 — TEST OUT 6 SEL
  [14:8] TESTSEL5 — TEST OUT 5 SEL
  [6:0] TESTSEL4 — TEST OUT 4 SEL
0x134 IXCINPUTSEL — IxC Input Signal Select REGISTER
  [18] I3C04_SDA_SEL — SELECT I3C04 SDA GPIO
    0=GPIO017 (GPIO017 (I3C04_SDAa)); 1=GPIO103 (GPIO103 (I3C04_SDAb))
  [17] I3C04_SCL_SEL — SELECT I3C04 SCL GPIO
    0=GPIO014 (GPIO014 (I3C04_SCLa)); 1=GPIO102 (GPIO102 (I3C04_SCLb))
  [16] I2C11_SDA_SEL — SELECT I2C11 SDA GPIO
    0=GPIO071 (GPIO071 (I2C11_SDAa)); 1=GPIO099 (GPIO099 (I2C11_SDAb))
  [15] I2C11_SCL_SEL — SELECT I2C11 SCL GPIO
    0=GPIO072 (GPIO072 (I2C11_SCLa)); 1=GPIO098 (GPIO098 (I2C11_SCLb))
  [14] I2C10_SDA_SEL — SELECT I2C10 SDA GPIO
    0=GPIO149 (GPIO149 (I2C10_SDAa)); 1=GPIO097 (GPIO097 (I2C10_SDAb))
  [13] I2C10_SCL_SEL — SELECT I2C10 SCL GPIO
    0=GPIO096 (GPIO096 (I2C10_SCLa)); 1=GPIO152 (GPIO152 (I2C10_SCLb))
  [12] I2C9_SDA_SEL — SELECT I2C09 SDA GPIO
    0=GPIO148 (GPIO148 (I2C09_SDAa)); 1=GPIO152 (GPIO152 (I2C09_SDAb))
  [11] I2C9_SCL_SEL — SELECT I2C09 SCL GPIO
    0=GPIO144 (GPIO144 (I2C09_SCLa)); 1=GPIO151 (GPIO151 (I2C09_SCLb))
  [10] I2C8_SDA_SEL — SELECT I2C08 SDA GPIO
    0=GPIO112 (GPIO112 (I2C08_SDAa)); 1=GPIO147 (GPIO147 (I2C08_SDAb))
  [9] I2C8_SCL_SEL — SELECT I2C08 SCL GPIO
    0=GPIO146 (GPIO146 (I2C08_SCLa)); 1=GPIO150 (GPIO150 (I2C08_SCLb))
  [8] I2C6_SDA_SEL — SELECT I2C06 SDA GPIO
    0=GPIO025 (GPIO025 (I2C06_SDAa)); 1=GPIO101 (GPIO101 (I2C06_SDAb))
  [7] I2C6_SCL_SEL — SELECT I2C06 SCL GPIO
    0=GPIO024 (GPIO024 (I2C06_SCLa)); 1=GPIO100 (GPIO100 (I2C06_SCLb))
  [6] I2C4_SDA_SEL — SELECT I2C04 SDA GPIO
    0=GPIO069 (GPIO069 (I2C04_SDAa)); 1=GPIO116 (GPIO116 (I2C04_SDAb))
  [5] I2C4_SCL_SEL — SELECT I2C04 SCL GPIO
    0=GPIO070 (GPIO070 (I2C04_SCLa)); 1=GPIO113 (GPIO113 (I2C04_SCLb))
  [4] I2C3_SDA_SEL — SELECT I2C03 SDA GPIO
    0=GPIO138 (GPIO138 (I2C03_SDAa)); 1=GPIO142 (GPIO142 (I2C03_SDAb))
  [3:2] I2C3_SCL_SEL — SELECT I2C03 SCL GPIO
    0=GPIO012 (GPIO012 (I2C03_SCLa)); 1=GPIO136 (GPIO136 (I2C03_SCLb)); 2=GPIO143 (GPIO143 (I2C03_SCLc))
  [1] I2C1_SDA_SEL — SELECT I2C01 SDA GPIO
    0=GPIO077 (GPIO077 (I2C01_SDAa)); 1=GPIO105 (GPIO105 (I2C01_SDAb))
  [0] I2C1_SCL_SEL — SELECT I2C01 SCL GPIO
    0=GPIO078 (GPIO078 (I2C01_SCLa)); 1=GPIO104 (GPIO104 (I2C01_SCLb))
0x138 UART_LPT_INPUT_SEL — UART LPT Input Signal Select REGISTER
  [28] UART02_RX_SEL — SELECT UART02 RX GPIO
    0=GPIO047 (GPIO047 (UART02_RXa)); 1=GPIO113 (GPIO113 (UART02_RXb))
  [27] UART02_RI_SEL — SELECT UART02 RI GPIO
    0=GPIO052 (GPIO052 (UART02_RIa)); 1=GPIO090 (GPIO090 (UART02_RIb))
  [26:25] UART02_DSR_SEL — SELECT UART02 DSR GPIO
    0=GPIO054 (GPIO054 (UART02_DSRa)); 1=GPIO086 (GPIO086 (UART02_DSRb)); 2=GPIO089 (GPIO089 (UART02_DSRc))
  [24:23] UART02_DCD_SEL — SELECT UART02 DCD GPIO
    0=GPIO051 (GPIO051 (UART02_DCDa)); 1=GPIO085 (GPIO085 (UART02_DCDb)); 2=GPIO088 (GPIO088 (UART02_DCDc))
  [22:21] UART02_CTS_SEL — SELECT UART02 CTS GPIO
    0=GPIO053 (GPIO053 (UART02_CTSa)); 1=GPIO071 (GPIO071 (UART02_CTSb)); 2=GPIO087 (GPIO087 (UART02_CTSc))
  [20:19] UART01_RI_SEL — SELECT UART01 RI GPIO
    0=GPIO033 (GPIO033 (UART01_RIa)); 1=GPIO112 (GPIO112 (UART01_RIb)); 2=GPIO151 (GPIO151 (UART01_RIc))
  [18] UART01_DSR_SEL — SELECT UART01 DSR GPIO
    0=GPIO032 (GPIO032 ((UART01_DSRa)); 1=GPIO143 (GPIO143 ((UART01_DSRb))
  [17:16] UART01_CTS_SEL — SELECT UART01 CTS GPIO
    0=GPIO027 (GPIO027 (UART01_CTSa)); 1=GPIO035 (GPIO035 (UART01_CTSb)); 2=GPIO138 (GPIO138 (UART01_CTSc)); 3=GPIO142 (GPIO142 (UART01_CTSd))
  [15:14] UART01_DCD_SEL — SELECT UART01 DCD GPIO
    0=GPIO019 (GPIO019 (UART01_DCDa)); 1=GPIO031 (GPIO031 (UART01_DCDb)); 2=GPIO117 (GPIO117 (UART01_DCDc)); 3=GPIO148 (GPIO148 (UART01_DCDd))
  [13] UART01_RX_SEL — SELECT UART01 RX GPIO
    0=GPIO012 (GPIO012 (UART01_RXa)); 1=GPIO146 (GPIO146 (UART01_RXb))
  [12] LPT_SLCT_SEL — SELECT LPT_SLCT GPIO
    0=GPIO044 (GPIO044 (LPT_SLCTa)); 1=GPIO095 (GPIO095 (LPT_SLCTb))
  [11] LPT_PE_SEL — SELECT LPT_PE GPIO
    0=GPIO040 (GPIO040 (LPT_PEa)); 1=GPIO113 (GPIO113 (LPT_PEb))
  [10] LPT_ERR_SEL — SELECT LPT_ERR GPIO
    0=GPIO043 (GPIO043 (LPT_ERRa)); 1=GPIO094 (GPIO094 (LPT_ERRb))
  [n+2] LPT_D{n}_SEL (n=0..7) — SELECT LPT_D{n} GPIO
    0=GPIO{n+30:03} (GPIO{n+30:03} (LPT_D{n}a)); 1=GPIO{n+44:03} (GPIO{n+44:03} (LPT_D{n}b))
  [1] LPT_BUSY_SEL — SELECT LPT BUSY GPIO
    0=GPIO039 (GPIO039 (LPT_BUSYa)); 1=GPIO053 (GPIO053 (LPT_BUSYb))
  [0] LPT_ACK_SEL — SELECT LPT ACK GPIO
    0=GPIO038 (GPIO038 (LPT_ACK_Na)); 1=GPIO052 (GPIO052 (LPT_ACK_Nb))
0x13C IP_INPUT_SEL — IP Input Signal Select REGISTER
  [31:30] PWRBTN_SEL — SELECT PWRBTN GPIO
    0=GPIO129 (GPIO129 (PWRBTNa)); 1=GPIO131 (GPIO131 (PWRBTNb)); 2=GPIO135 (GPIO135 (PWRBTNc))
  [29] PS2_DATA2_SEL — SELECT PS2 DATA2 GPIO
    0=GPIO016 (GPIO016 (PS2_DATA02a)); 1=GPIO099 (GPIO099 (PS2_DATA02b))
  [28] PS2_CLK2_SEL — SELECT PS2 CLK2 GPIO
    0=GPIO015 (GPIO015 (PS2_CLK02a)); 1=GPIO098 (GPIO098 (PS2_CLK02b))
  [27] PS2_DATA1_SEL — SELECT PS2 DATA1 GPIO
    0=GPIO017 (GPIO017 (PS2_DATA01a)); 1=GPIO067 (GPIO067 (PS2_DATA01b))
  [26:25] PS2_CLK1_SEL — SELECT PS2 CLK01 GPIO
    0=GPIO014 (GPIO014 (PS2_CLK01a)); 1=GPIO060 (GPIO060 (PS2_CLK01b)); 2=GPIO068 (GPIO068 (PS2_CLK01c))
  [24] LEDSTP_SEL — SELECT LEDSTP GPIO
    0=GPIO076 (GPIO076 (LEDSTPa)); 1=GPIO145 (GPIO145 (LEDSTPb))
  [n+16] KSI{n}_SEL (n=4..7) — SELECT KSI{n} GPIO
    0=GPIO{n+50:03} (GPIO{n+50:03} (KSI{n}a)); 1=GPIO{n+88:03} (GPIO{n+88:03} (KSI{n}b))
  [19] CEC2_SEL — SELECT CEC2 GPIO
    0=GPIO001 (GPIO001 (CEC2a)); 1=GPIO079 (GPIO079 (CEC2b))
  [18] CEC1_SEL — SELECT CEC1 GPIO
    0=GPIO128 (GPIO128 (CEC1a)); 1=GPIO151 (GPIO151 (CEC1b))
  [17] SPIC01_IO3_SEL — SELECT SPIC01 IO3 GPIO
    0=GPIO072 (GPIO072 (SPIC_IO3a)); 1=GPIO149 (GPIO149 (SPIC_IO3b))
  [16] SPIC01_IO2_SEL — SELECT SPIC01 IO2 GPIO
    0=GPIO034 (GPIO034 (SPIC_IO2a)); 1=GPIO119 (GPIO119 (SPIC_IO2b))
  [15] SPIC01_IO1_SEL — SELECT SPIC01 IO1 GPIO
    0=GPIO031 (GPIO031 (SPIC_IO1a)); 1=GPIO124 (GPIO124 (SPIC_IO1b))
  [14] SPIC01_IO0_SEL — SELECT SPIC01 IO0 GPIO
    0=GPIO032 (GPIO032 (SPIC_IO0a)); 1=GPIO123 (GPIO123 (SPIC_IO0b))
  [13] TACH08_SEL — SELECT TACH08 GPIO
    0=GPIO038 (GPIO038 (TACHO08a)); 1=GPIO118 (GPIO118 (TACHO08b))
  [12] TACH07_SEL — SELECT TACH07 GPIO
    0=GPIO037 (GPIO037 (TACHO07a)); 1=GPIO117 (GPIO117 (TACHO07b))
  [11:10] TACH06_SEL — SELECT TACH06 GPIO
    0=GPIO036 (GPIO036 (TACHO06a)); 1=GPIO055 (GPIO055 (TACHO06b)); 2=GPIO089 (GPIO089 (TACHO06c))
  [9:8] TACH05_SEL — SELECT TACH05 GPIO
    0=GPIO013 (GPIO013 (TACHO05a)); 1=GPIO088 (GPIO088 (TACHO05b)); 2=GPIO141 (GPIO141 (TACHO05c))
  [7:6] TACH04_SEL — SELECT TACH04 GPIO
    0=GPIO115 (GPIO115 (TACHO04a)); 1=GPIO127 (GPIO127 (TACHO04b)); 2=GPIO152 (GPIO152 (TACHO04c))
  [5:4] TACH03_SEL — SELECT TACH03 GPIO
    0=GPIO042 (GPIO042 (TACHO03a)); 1=GPIO144 (GPIO144 (TACHO03b)); 2=GPIO146 (GPIO146 (TACHO03c))
  [3:2] TACH02_SEL — SELECT TACH02 GPIO
    0=GPIO025 (GPIO025 (TACHO02a)); 1=GPIO075 (GPIO075 (TACHO02b)); 2=GPIO147 (GPIO147 (TACHO02c))
  [1:0] TACH01_SEL — SELECT TACH01 GPIO
    0=GPIO021 (GPIO021 (TACHO01a)); 1=GPIO041 (GPIO041 (TACHO01b)); 2=GPIO074 (GPIO074 (TACHO01c))
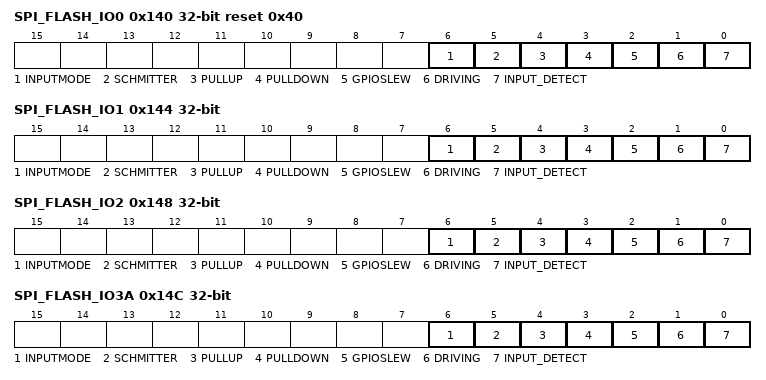
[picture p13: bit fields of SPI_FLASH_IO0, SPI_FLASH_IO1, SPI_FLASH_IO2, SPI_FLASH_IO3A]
0x140 SPI_FLASH_IO0 reset 0x40 — spi_flash_io0 CONTROL REGISTER
  [6] INPUTMODE — INPUT DRIVING
    0=3.3V; 1=1.8V
  [5] SCHMITTER — SCHMITTER Disable
    0=DISABLE; 1=ENABLE
  [4] PULLUP — PULL UP Disable
    0=DISABLE; 1=ENABLE
  [3] PULLDOWN — PULL DOWN Disable
    0=DISABLE; 1=ENABLE
  [2] GPIOSLEW — Gpio output value
    0=FAST; 1=SLOW
  [1] DRIVING
    0=8mA; 1=12mA
  [0] INPUT_DETECT — Input detection
    0=DISABLE; 1=ENABLE
0x144 SPI_FLASH_IO1 — spi_flash_io1 CONTROL REGISTER
  fields as SPI_FLASH_IO0
0x148 SPI_FLASH_IO2 — spi_flash_io2 CONTROL REGISTER
  fields as SPI_FLASH_IO0
0x14C SPI_FLASH_IO3A — spi_flash_io3a CONTROL REGISTER
  fields as SPI_FLASH_IO0
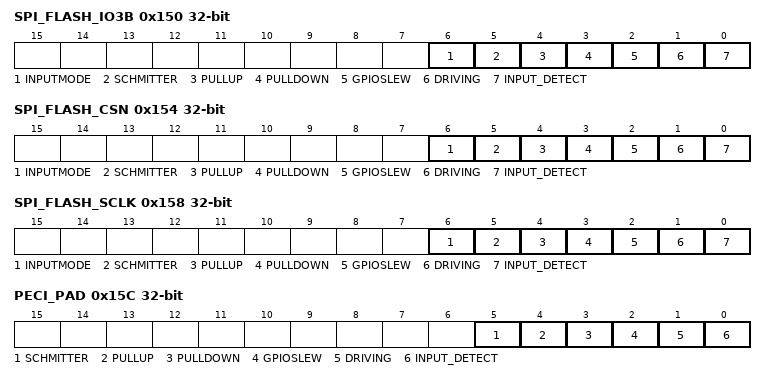
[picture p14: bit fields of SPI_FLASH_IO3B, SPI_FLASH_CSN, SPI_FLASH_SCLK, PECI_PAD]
0x150 SPI_FLASH_IO3B — spi_flash_io3B CONTROL REGISTER
  fields as SPI_FLASH_IO0
0x154 SPI_FLASH_CSN — spi_flash_CSN CONTROL REGISTER
  fields as SPI_FLASH_IO0
0x158 SPI_FLASH_SCLK — spi_flash_SCLK CONTROL REGISTER
  fields as SPI_FLASH_IO0
0x15C PECI_PAD — PECI_PAD CONTROL REGISTER
  [5] SCHMITTER — SCHMITTER Disable
    0=DISABLE; 1=ENABLE
  [4] PULLUP — PULL UP Disable
    0=DISABLE; 1=ENABLE
  [3] PULLDOWN — PULL DOWN Disable
    0=DISABLE; 1=ENABLE
  [2] GPIOSLEW — Gpio output value
    0=FAST; 1=SLOW
  [1] DRIVING
    0=8mA; 1=12mA
  [0] INPUT_DETECT — Input detection
    0=DISABLE; 1=ENABLE
0x160 VREF_VTT_PAD — VREF_VTT PAD CONTROL REGISTER
  [0] vref_vtt_pwr_cut
    0=DISABLE (disable VREF_VTT function(GPIO121/I2C02_DATA mode)); 1=ENABLE (enable VREF_VTT function(VREF_VTT mode))
0x164 ESPI_CLK_PAD reset 0x21 — ESPI_CLK PAD CONTROL REGISTER
  [7] PWRCUT — espi_clk_pwr_cut
    0=DISABLE (disable espi_clk pad power); 1=ENABLE (enable espi_clk pad power)
  [6] INPUTMODE — INPUT DRIVING
    0=3.3V; 1=1.8V
  [5] SCHMITTER — SCHMITTER Disable
    0=DISABLE; 1=ENABLE
  [4] PULLUP — PULL UP Disable
    0=DISABLE; 1=ENABLE
  [3] PULLDOWN — PULL DOWN Disable
    0=DISABLE; 1=ENABLE
  [2] GPIOSLEW — Gpio output value
    0=FAST; 1=SLOW
  [1] DRIVING
    0=4mA; 1=8mA
  [0] INPUT_DETECT — Input detection
    0=DISABLE; 1=ENABLE
{0x168+4i} ESPI_IO{i}_PAD reset 0x21 (i=0..3) — ESPI_IO{i} PAD CONTROL REGISTER
  [7] PWRCUT — espi_clk_pwr_cut
    0=DISABLE (disable espi_io{i} pad power); 1=ENABLE (enable espi_io{i} pad power)
  [6] INPUTMODE — INPUT DRIVING
    0=3.3V; 1=1.8V
  [5] SCHMITTER — SCHMITTER Disable
    0=DISABLE; 1=ENABLE
  [4] PULLUP — PULL UP Disable
    0=DISABLE; 1=ENABLE
  [3] PULLDOWN — PULL DOWN Disable
    0=DISABLE; 1=ENABLE
  [2] GPIOSLEW — Gpio output value
    0=FAST; 1=SLOW
  [1] DRIVING
    0=4mA; 1=8mA
  [0] INPUT_DETECT — Input detection
    0=DISABLE; 1=ENABLE
0x178 GPIOSTS0 ro — GPIO STATUS REGISTER
  [n] GPIO{n:03} (n=0..31) — GPIO{n:03} STATUS Monitor
0x17C GPIOSTS1 ro — GPIO1 STATUS REGISTER
  [n-32] GPIO{n:03} (n=32..63) — GPIO{n:03} STATUS Monitor
0x180 GPIOSTS2 ro — GPIO2 STATUS REGISTER
  [n-64] GPIO{n:03} (n=64..95) — GPIO{n:03} STATUS Monitor
0x184 GPIOSTS3 ro — GPIO3 STATUS REGISTER
  [n-96] GPIO{n:03} (n=96..127) — GPIO{n:03} STATUS Monitor
0x188 GPIOSTS4 ro — GPIO4 STATUS REGISTER
  [n-128] GPIO{n} (n=128..152) — GPIO{n} STATUS Monitor
